# APM32F072 register map
File version: 1.0
Registers are 32-bit, read-write, reset 0x0 unless marked. A register's access mark holds for its fields unless they carry their own. Offsets are from the block's base; [hi:lo] are bit positions; lines under a group give offsets from that group; {n}, {i} and the like mark numbered series.

## SYSCFG — System configuration controller
Base 0x40010000
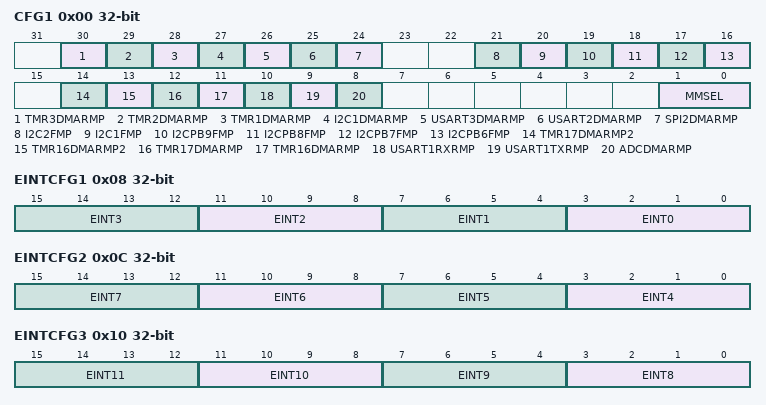
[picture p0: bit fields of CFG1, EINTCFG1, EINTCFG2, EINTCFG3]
0x00 CFG1 — configuration register 1
  [30] TMR3DMARMP — TMR3 DMA request remapping bit
  [29] TMR2DMARMP — TMR2 DMA request remapping bit
  [28] TMR1DMARMP — TMR1 DMA request remapping bit
  [27] I2C1DMARMP — I2C1 DMA request remapping bit
  [26] USART3DMARMP — USART3 DMA request remapping bit
  [25] USART2DMARMP — USART2 DMA request remapping bit
  [24] SPI2DMARMP — SPI2 DMA request remapping bit.
  [21] I2C2FMP — FM+ driving capability activation for I2C1
  [20] I2C1FMP — FM+ driving capability activation for I2C1
  [19] I2CPB9FMP — Fast Mode Plus (FM+) driving capability activation bits.
  [18] I2CPB8FMP — Fast Mode Plus (FM+) driving capability activation bits.
  [17] I2CPB7FMP — Fast Mode Plus (FM+) driving capability activation bits.
  [16] I2CPB6FMP — Fast Mode Plus (FM plus) driving capability activation bits.
  [14] TMR17DMARMP2 — TMR17 alternate DMA request remapping bit.
  [13] TMR16DMARMP2 — TMR16 alternate DMA request remapping bit.
  [12] TMR17DMARMP — TMR17 DMA request remapping bit
  [11] TMR16DMARMP — TMR16 DMA request remapping bit
  [10] USART1RXRMP — USART1_RX DMA request remapping bit
  [9] USART1TXRMP — USART1_TX DMA remapping bit
  [8] ADCDMARMP — ADC DMA remapping bit
  [1:0] MMSEL — Memory mapping selection bits
0x08 EINTCFG1 — external interrupt configuration register 1
  [4n+3:4n] EINT{n} (n=0..3) — EINT {n} configuration bits
0x0C EINTCFG2 — external interrupt configuration register 2
  [4n-13:4n-16] EINT{n} (n=4..7) — EINT {n} configuration bits
0x10 EINTCFG3 — external interrupt configuration register 3
  [4n-29:4n-32] EINT{n} (n=8..11) — EINT {n} configuration bits
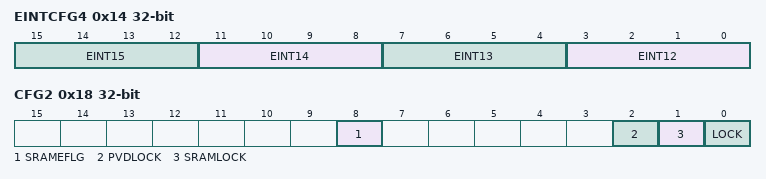
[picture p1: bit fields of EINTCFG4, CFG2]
0x14 EINTCFG4 — external interrupt configuration register 4
  [4n-45:4n-48] EINT{n} (n=12..15) — EINT {n} configuration bits
0x18 CFG2 — configuration register 2
  [8] SRAMEFLG — SRAM parity error flag
  [2] PVDLOCK — PVD lock enable bit
  [1] SRAMLOCK — SRAM parity lock bit
  [0] LOCK — Cortex-M0 Hardfault enable bit

## TSC — Touch sensing controller
Base 0x40024000
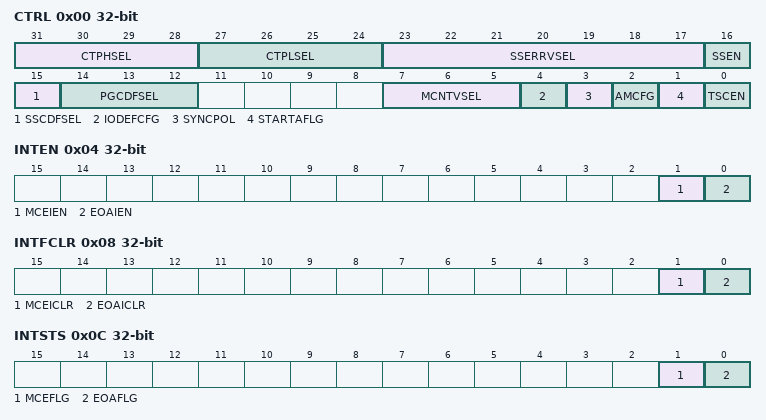
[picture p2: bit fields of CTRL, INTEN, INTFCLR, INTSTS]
0x00 CTRL — control register
  [31:28] CTPHSEL — Charge transfer pulse high
  [27:24] CTPLSEL — Charge transfer pulse low
  [23:17] SSERRVSEL — Spread spectrum deviation
  [16] SSEN — Spread spectrum enable
  [15] SSCDFSEL — Spread spectrum prescaler
  [14:12] PGCDFSEL — pulse generator prescaler
  [7:5] MCNTVSEL — Max count error value
  [4] IODEFCFG — I/O Default mode
  [3] SYNCPOL — Synchronization pin polarity
  [2] AMCFG — Acquisition mode
  [1] STARTAFLG — Start a new acquisition
  [0] TSCEN — Touch sensing controller enable
0x04 INTEN — interrupt enable register
  [1] MCEIEN — Max count error interrupt enable
  [0] EOAIEN — End of acquisition interrupt enable
0x08 INTFCLR — interrupt clear register
  [1] MCEICLR — Max count error interrupt clear
  [0] EOAICLR — End of acquisition interrupt clear
0x0C INTSTS — interrupt status register
  [1] MCEFLG — Max count error flag
  [0] EOAFLG — End of acquisition flag
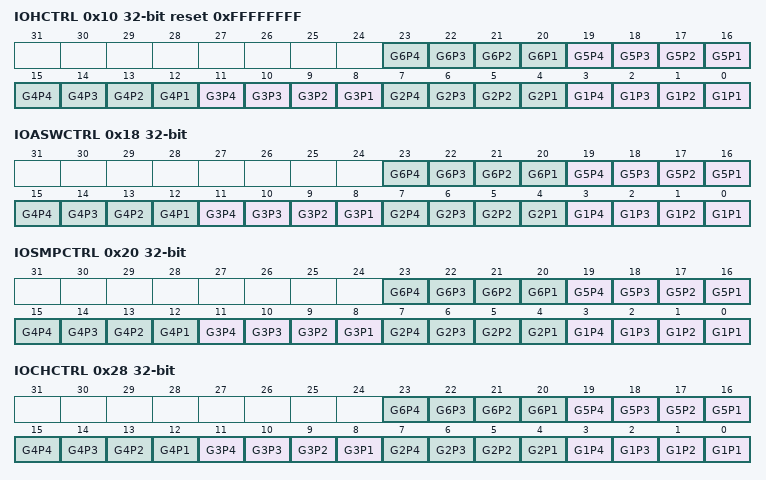
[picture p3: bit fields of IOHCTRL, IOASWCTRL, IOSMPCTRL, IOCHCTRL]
0x10 IOHCTRL reset 0xFFFFFFFF — I/O hysteresis control register
  [4n-1] G{n}P4 (n=1..6) — G{n}P4 Schmitt trigger hysteresis mode
  [4n-2] G{n}P3 (n=1..6) — G{n}P3 Schmitt trigger hysteresis mode
  [4n-3] G{n}P2 (n=1..6) — G{n}P2 Schmitt trigger hysteresis mode
  [4n-4] G{n}P1 (n=1..6) — G{n}P1 Schmitt trigger hysteresis mode
0x18 IOASWCTRL — I/O analog switch control register
  [4n-1] G{n}P4 (n=1..6) — G{n}P4 analog switch enable
  [4n-2] G{n}P3 (n=1..6) — G{n}P3 analog switch enable
  [4n-3] G{n}P2 (n=1..6) — G{n}P2 analog switch enable
  [4n-4] G{n}P1 (n=1..6) — G{n}P1 analog switch enable
0x20 IOSMPCTRL — I/O sampling control register
  [4n-1] G{n}P4 (n=1..6) — G{n}P4 sampling mode
  [4n-2] G{n}P3 (n=1..6) — G{n}P3 sampling mode
  [4n-3] G{n}P2 (n=1..6) — G{n}P2 sampling mode
  [4n-4] G{n}P1 (n=1..6) — G{n}P1 sampling mode
0x28 IOCHCTRL — I/O channel control register
  [4n-1] G{n}P4 (n=1..6) — G{n}P4 channel mode
  [4n-2] G{n}P3 (n=1..6) — G{n}P3 channel mode
  [4n-3] G{n}P2 (n=1..6) — G{n}P2 channel mode
  [4n-4] G{n}P1 (n=1..6) — G{n}P1 channel mode
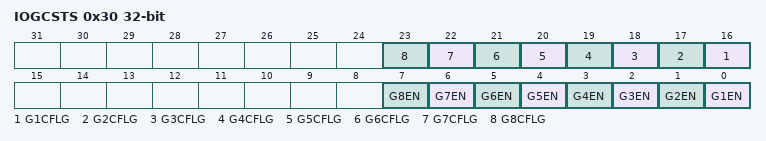
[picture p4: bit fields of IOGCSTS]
0x30 IOGCSTS access per field — I/O group control status register
  [n+15] G{n}CFLG ro (n=1..8) — Analog I/O group x status
  [n-1] G{n}EN rw (n=1..8) — Analog I/O group x enable
{0x30+4i} IOG{i}CNT ro (i=1..8) — I/O group x counter register
  [13:0] CNTVAL — Counter value
